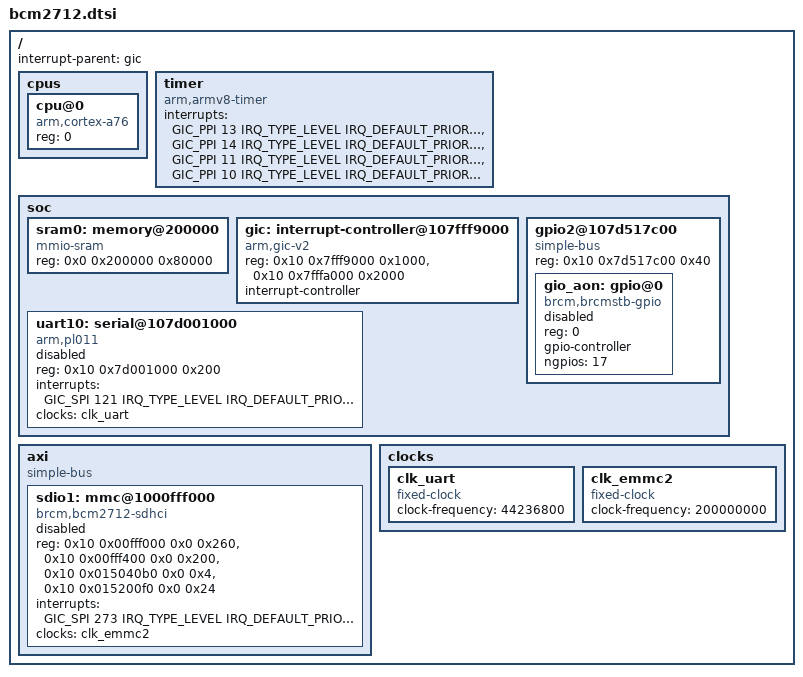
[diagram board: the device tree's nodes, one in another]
/*
 * Copyright 2024 Myeonghyeon Park <myeonghyeon@tsnlab.com>
 *
 * SPDX-License-Identifier: Apache-2.0
 */

#include <arm64/armv8-a.dtsi>
#include <zephyr/dt-bindings/interrupt-controller/arm-gic.h>

/ {
	cpus {
		#address-cells = <1>;
		#size-cells = <0>;

		cpu@0 {
			device_type = "cpu";
			compatible = "arm,cortex-a76";
			reg = <0>;
		};
	};

	interrupt-parent = <&gic>;

	timer {
		compatible = "arm,armv8-timer";
		interrupts = <GIC_PPI 13 IRQ_TYPE_LEVEL
			      IRQ_DEFAULT_PRIORITY>,
			     <GIC_PPI 14 IRQ_TYPE_LEVEL
			      IRQ_DEFAULT_PRIORITY>,
			     <GIC_PPI 11 IRQ_TYPE_LEVEL
			      IRQ_DEFAULT_PRIORITY>,
			     <GIC_PPI 10 IRQ_TYPE_LEVEL
			      IRQ_DEFAULT_PRIORITY>;
	};

	soc {
		#address-cells = <2>;
		#size-cells = <1>;

		sram0: memory@200000 {
			device_type = "memory";
			compatible = "mmio-sram";
			reg = <0x0 0x200000 0x80000>;
		};

		gic: interrupt-controller@107fff9000 {
			compatible = "arm,gic-v2", "arm,gic";
			reg = <0x10 0x7fff9000 0x1000>,
			      <0x10 0x7fffa000 0x2000>;
			interrupt-controller;
			#interrupt-cells = <4>;
			status = "okay";
		};

		gpio2@107d517c00 {
			compatible = "simple-bus";
			reg = <0x10 0x7d517c00 0x40>;

			#address-cells = <1>;
			#size-cells = <0>;
			gio_aon: gpio@0 {
				compatible = "brcm,brcmstb-gpio";
				reg = <0>;
				gpio-controller;
				#gpio-cells = <2>;
				ngpios = <17>;
				status = "disabled";
			};
		};

		uart10: serial@107d001000 {
			compatible = "arm,pl011";
			reg = <0x10 0x7d001000 0x200>;
			interrupts = <GIC_SPI 121 IRQ_TYPE_LEVEL
				      IRQ_DEFAULT_PRIORITY>;
			interrupt-names = "irq_121";
			clocks = <&clk_uart>;
			status = "disabled";
		};
	};

	axi: axi {
		compatible = "simple-bus";
		#address-cells = <2>;
		#size-cells = <2>;

		sdio1: mmc@1000fff000 {
			compatible = "brcm,bcm2712-sdhci";
			reg = <0x10 0x00fff000  0x0 0x260>,
			      <0x10 0x00fff400  0x0 0x200>,
			      <0x10 0x015040b0  0x0 0x4>,  // Bus isolation control
			      <0x10 0x015200f0  0x0 0x24>; // LCPLL control misc0-8
			reg-names = "host", "cfg", "busisol", "lcpll";
			interrupts = <GIC_SPI 273 IRQ_TYPE_LEVEL IRQ_DEFAULT_PRIORITY>;
			clocks = <&clk_emmc2>;
			status = "disabled";
		};
	};

	clocks {
		clk_uart: clk_uart {
			compatible = "fixed-clock";
			clock-frequency = <44236800>;
			#clock-cells = <0>;
		};

		clk_emmc2: clk_emmc2 {
			#clock-cells = <0>;
			compatible = "fixed-clock";
			clock-frequency = <200000000>;
		};
	};
};
